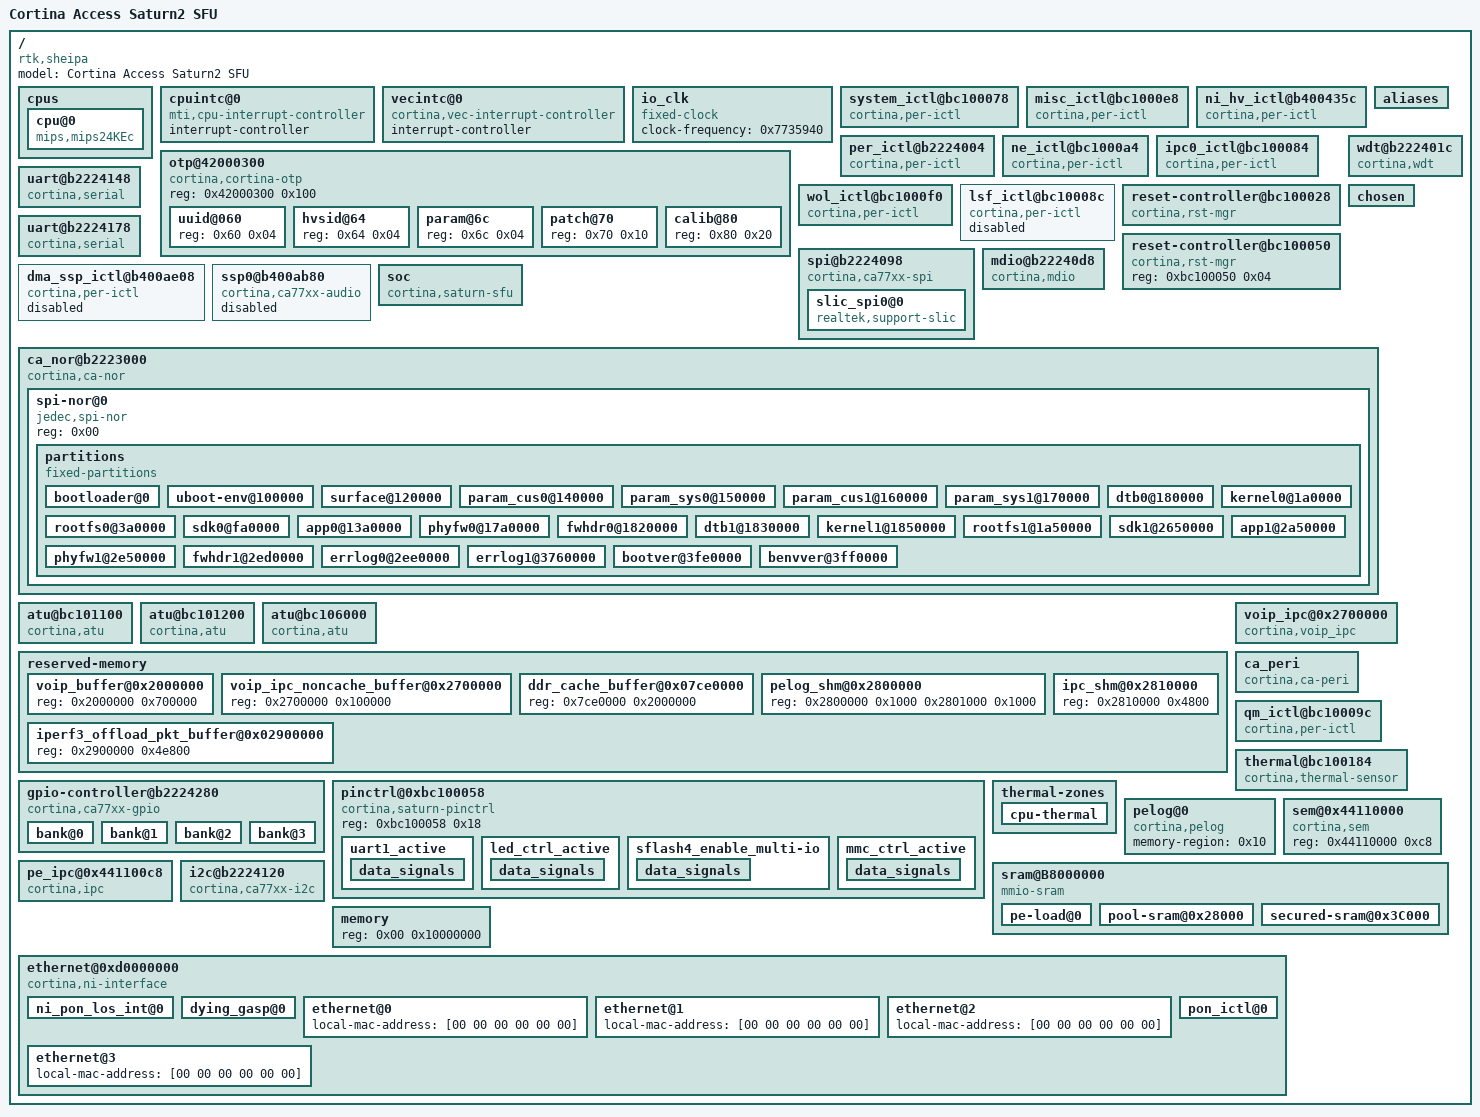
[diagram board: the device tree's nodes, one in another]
/dts-v1/;

/ {
	compatible = "rtk,sheipa";
	#address-cells = <0x01>;
	#size-cells = <0x01>;
	model = "Cortina Access Saturn2 SFU";

	cpus {
		#address-cells = <0x01>;
		#size-cells = <0x00>;

		cpu@0 {
			compatible = "mips,mips24KEc";
		};
	};

	cpuintc@0 {
		#address-cells = <0x00>;
		#interrupt-cells = <0x01>;
		interrupt-controller;
		compatible = "mti,cpu-interrupt-controller";
		linux,phandle = <0x01>;
		phandle = <0x01>;
	};

	vecintc@0 {
		#address-cells = <0x00>;
		#interrupt-cells = <0x01>;
		interrupt-controller;
		compatible = "cortina,vec-interrupt-controller";
		linux,phandle = <0x04>;
		phandle = <0x04>;
	};

	io_clk {
		compatible = "fixed-clock";
		#clock-cells = <0x00>;
		clock-frequency = <0x7735940>;
		linux,phandle = <0x05>;
		phandle = <0x05>;
	};

	otp@42000300 {
		compatible = "cortina,cortina-otp";
		#address-cells = <0x01>;
		#size-cells = <0x01>;
		reg = <0x42000300 0x100>;

		uuid@060 {
			reg = <0x60 0x04>;
		};

		hvsid@64 {
			reg = <0x64 0x04>;
		};

		param@6c {
			reg = <0x6c 0x04>;
			linux,phandle = <0x15>;
			phandle = <0x15>;
		};

		patch@70 {
			reg = <0x70 0x10>;
		};

		calib@80 {
			reg = <0x80 0x20>;
			linux,phandle = <0x16>;
			phandle = <0x16>;
		};
	};

	system_ictl@bc100078 {
		compatible = "cortina,per-ictl";
		reg = <0xbc100078 0x08>;
		interrupt-controller;
		#interrupt-cells = <0x01>;
		interrupt-parent = <0x01>;
		interrupts = <0x02>;
		linux,phandle = <0x02>;
		phandle = <0x02>;
	};

	misc_ictl@bc1000e8 {
		compatible = "cortina,per-ictl";
		reg = <0xbc1000e8 0x08>;
		interrupt-controller;
		#interrupt-cells = <0x01>;
		interrupt-parent = <0x02>;
		interrupts = <0x00>;
	};

	ni_hv_ictl@b400435c {
		compatible = "cortina,per-ictl";
		reg = <0xb400435c 0x08>;
		interrupt-controller;
		#interrupt-cells = <0x01>;
		interrupt-parent = <0x03>;
		interrupts = <0x00>;
		linux,phandle = <0x14>;
		phandle = <0x14>;
	};

	per_ictl@b2224004 {
		compatible = "cortina,per-ictl";
		reg = <0xb2224004 0x08>;
		interrupt-controller;
		#interrupt-cells = <0x01>;
		interrupt-parent = <0x01>;
		interrupts = <0x03>;
		linux,phandle = <0x06>;
		phandle = <0x06>;
	};

	ne_ictl@bc1000a4 {
		compatible = "cortina,per-ictl";
		reg = <0xbc1000a4 0x08>;
		interrupt-controller;
		#interrupt-cells = <0x01>;
		interrupt-parent = <0x04>;
		interrupts = <0x04>;
		linux,phandle = <0x03>;
		phandle = <0x03>;
	};

	ipc0_ictl@bc100084 {
		compatible = "cortina,per-ictl";
		reg = <0xbc100084 0x08>;
		interrupt-controller;
		#interrupt-cells = <0x01>;
		interrupt-parent = <0x04>;
		interrupts = <0x06>;
		linux,phandle = <0x12>;
		phandle = <0x12>;
	};

	wol_ictl@bc1000f0 {
		compatible = "cortina,per-ictl";
		reg = <0xbc1000f0 0x08>;
		interrupt-controller;
		#interrupt-cells = <0x01>;
		interrupt-parent = <0x03>;
		interrupts = <0x07>;
	};

	lsf_ictl@bc10008c {
		compatible = "cortina,per-ictl";
		reg = <0xbc10008c 0x08>;
		interrupt-controller;
		#interrupt-cells = <0x01>;
		interrupt-parent = <0x01>;
		interrupts = <0x05>;
		status = "disabled";
		linux,phandle = <0x08>;
		phandle = <0x08>;
	};

	reset-controller@bc100028 {
		compatible = "cortina,rst-mgr";
		reg = <0xbc100028 0x04>;
		#reset-cells = <0x01>;
		init-state = <0x4f28022e>;
		linux,phandle = <0x0d>;
		phandle = <0x0d>;
	};

	reset-controller@bc100050 {
		compatible = "cortina,rst-mgr";
		reg = <0xbc100050 0x04>;
		#reset-cells = <0x01>;
		linux,phandle = <0x17>;
		phandle = <0x17>;
	};

	aliases {
		serial0 = "/uart@b2224148";
		serial1 = "/uart@b2224178";
		ethernet0 = "/ethernet@0xd0000000/ethernet@0";
		ethernet1 = "/ethernet@0xd0000000/ethernet@1";
		ethernet2 = "/ethernet@0xd0000000/ethernet@2";
		ethernet3 = "/ethernet@0xd0000000/ethernet@3";
	};

	uart@b2224148 {
		device_type = "serial";
		compatible = "cortina,serial";
		reg = <0xb2224148 0x30>;
		clocks = <0x05>;
		interrupt-parent = <0x02>;
		interrupts = <0x04>;
	};

	uart@b2224178 {
		device_type = "serial";
		compatible = "cortina,serial";
		reg = <0xb2224178 0x30>;
		clocks = <0x05>;
		interrupt-parent = <0x02>;
		interrupts = <0x05>;
	};

	wdt@b222401c {
		compatible = "cortina,wdt";
		reg = <0xb222401c 0x30 0xbc100050 0x04>;
		interrupt-parent = <0x06>;
		interrupts = <0x04>;
		clocks = <0x05>;
		reset-on-timeout;
	};

	spi@b2224098 {
		compatible = "cortina,ca77xx-spi";
		reg = <0xb2224098 0x40>;
		interrupt-parent = <0x06>;
		interrupts = <0x05>;
		clocks = <0x05>;
		#address-cells = <0x01>;
		#size-cells = <0x00>;

		slic_spi0@0 {
			compatible = "realtek,support-slic";
			status = "okay";
			spi-max-frequency = <0x2625a0>;
			reg = <0x00>;
			reset-gpio = <0x07 0x0f 0x01>;
		};
	};

	dma_ssp_ictl@b400ae08 {
		compatible = "cortina,per-ictl";
		reg = <0xb400ae08 0x08>;
		interrupt-controller;
		#interrupt-cells = <0x01>;
		interrupt-parent = <0x08>;
		interrupts = <0x08>;
		status = "disabled";
		linux,phandle = <0x09>;
		phandle = <0x09>;
	};

	ssp0@b400ab80 {
		compatible = "cortina,ca77xx-audio";
		reg = <0xb400ab80 0x80 0xb400a064 0x08 0xb400aa80 0x80>;
		reg-names = "ssp\0dma-glb\0dma-ssp";
		interrupt-parent = <0x09>;
		interrupts = <0x06 0x02 0x03>;
		interrupt-names = "ssp\0dma-tx\0dma-rx";
		status = "disabled";
	};

	soc {
		compatible = "cortina,saturn-sfu";
		reg = <0xbc100000 0x04 0xbc109000 0x40 0xbc100034 0x04>;
		reg-names = "JTAG_ID\0CLOCK\0STRAP";
	};

	chosen {
		bootargs = "rd_start=0x86000000 rd_size=8018950 root=/dev/ram console=ttyS0,115200 rdinit=/sbin/init ";
	};

	mdio@b22240d8 {
		#address-cells = <0x01>;
		#size-cells = <0x00>;
		compatible = "cortina,mdio";
		reg = <0xb22240d8 0x48>;
		interrupt-parent = <0x06>;
		interrupts = <0x0c>;
		device_type = "mdio";
		clocks = <0x05>;
		clock-frequency = <0x7735940>;
	};

	ca_nor@b2223000 {
		compatible = "cortina,ca-nor";
		#address-cells = <0x01>;
		#size-cells = <0x00>;
		reg = <0xb2223000 0x50>;
		reg-names = "sflash-base";
		pinctrl-0 = <0x0a>;
		pinctrl-names = "default";

		spi-nor@0 {
			compatible = "jedec,spi-nor";
			reg = <0x00>;

			partitions {
				compatible = "fixed-partitions";
				#address-cells = <0x01>;
				#size-cells = <0x01>;

				bootloader@0 {
					label = "bootloader";
					reg = <0x00 0x100000>;
				};

				uboot-env@100000 {
					label = "uboot-env";
					reg = <0x100000 0x20000>;
				};

				surface@120000 {
					label = "surface";
					reg = <0x120000 0x20000>;
				};

				param_cus0@140000 {
					label = "param_cus0";
					reg = <0x140000 0x10000>;
				};

				param_sys0@150000 {
					label = "param_sys0";
					reg = <0x150000 0x10000>;
				};

				param_cus1@160000 {
					label = "param_cus1";
					reg = <0x160000 0x10000>;
				};

				param_sys1@170000 {
					label = "param_sys1";
					reg = <0x170000 0x10000>;
				};

				dtb0@180000 {
					label = "device-tree0";
					reg = <0x180000 0x20000>;
				};

				kernel0@1a0000 {
					label = "kernel0";
					reg = <0x1a0000 0x200000>;
				};

				rootfs0@3a0000 {
					label = "rootfs0";
					reg = <0x3a0000 0xc00000>;
				};

				sdk0@fa0000 {
					label = "sdk0";
					reg = <0xfa0000 0x400000>;
				};

				app0@13a0000 {
					label = "app0";
					reg = <0x13a0000 0x400000>;
				};

				phyfw0@17a0000 {
					label = "phyfw0";
					reg = <0x17a0000 0x80000>;
				};

				fwhdr0@1820000 {
					label = "fwhdr0";
					reg = <0x1820000 0x10000>;
				};

				dtb1@1830000 {
					label = "device-tree1";
					reg = <0x1830000 0x20000>;
				};

				kernel1@1850000 {
					label = "kernel1";
					reg = <0x1850000 0x200000>;
				};

				rootfs1@1a50000 {
					label = "rootfs1";
					reg = <0x1a50000 0xc00000>;
				};

				sdk1@2650000 {
					label = "sdk1";
					reg = <0x2650000 0x400000>;
				};

				app1@2a50000 {
					label = "app1";
					reg = <0x2a50000 0x400000>;
				};

				phyfw1@2e50000 {
					label = "phyfw1";
					reg = <0x2e50000 0x80000>;
				};

				fwhdr1@2ed0000 {
					label = "fwhdr1";
					reg = <0x2ed0000 0x10000>;
				};

				errlog0@2ee0000 {
					label = "errlog0";
					reg = <0x2ee0000 0x880000>;
				};

				errlog1@3760000 {
					label = "errlog1";
					reg = <0x3760000 0x880000>;
				};

				bootver@3fe0000 {
					label = "bootver";
					reg = <0x3fe0000 0x10000>;
				};

				benvver@3ff0000 {
					label = "benvver";
					reg = <0x3ff0000 0x10000>;
				};
			};
		};
	};

	atu@bc101100 {
		compatible = "cortina,atu";
		reg = <0xbc101100 0x1c>;
		reg-names = "taroko0_atu";
		atu-type = <0x00>;
		#iommu-cells = <0x00>;
		keep-init;
	};

	atu@bc101200 {
		compatible = "cortina,atu";
		reg = <0xbc101200 0x1c>;
		reg-names = "taroko1_atu";
		atu-type = <0x00>;
		#iommu-cells = <0x00>;
		keep-init;
	};

	atu@bc106000 {
		compatible = "cortina,atu";
		reg = <0xbc106000 0x1c>;
		reg-names = "eaxi_atu";
		atu-type = <0x00>;
		#iommu-cells = <0x00>;
		keep-init;
	};

	reserved-memory {
		#address-cells = <0x01>;
		#size-cells = <0x01>;
		ranges;

		voip_buffer@0x2000000 {
			reg = <0x2000000 0x700000>;
			linux,phandle = <0x0c>;
			phandle = <0x0c>;
		};

		voip_ipc_noncache_buffer@0x2700000 {
			reg = <0x2700000 0x100000>;
			linux,phandle = <0x0b>;
			phandle = <0x0b>;
		};

		ddr_cache_buffer@0x07ce0000 {
			reg = <0x7ce0000 0x2000000>;
			linux,phandle = <0x18>;
			phandle = <0x18>;
		};

		pelog_shm@0x2800000 {
			reg = <0x2800000 0x1000 0x2801000 0x1000>;
			linux,phandle = <0x10>;
			phandle = <0x10>;
		};

		ipc_shm@0x2810000 {
			reg = <0x2810000 0x4800>;
			linux,phandle = <0x11>;
			phandle = <0x11>;
		};

		iperf3_offload_pkt_buffer@0x02900000 {
			reg = <0x2900000 0x4e800>;
		};
	};

	voip_ipc@0x2700000 {
		compatible = "cortina,voip_ipc";
		reg = <0xb2224000 0x20 0x40000000 0x10>;
		memory-region = <0x0b 0x0c>;
		interrupt-parent = <0x06>;
		interrupts = <0x00>;
		resets = <0x0d 0x13 0x0d 0x15 0x0d 0x18>;
		reset-names = "pe_reset\0rcpu_reset\0pe_atu_reset";
	};

	ca_peri {
		compatible = "cortina,ca-peri";
		reg = <0xb2224018 0x1000 0xbc100000 0x200 0xba000800 0x10 0xba000000 0x400>;
		interrupt-parent = <0x06>;
		interrupts = <0x02>;
		interrupt-names = "TMR1";
	};

	qm_ictl@bc10009c {
		compatible = "cortina,per-ictl";
		reg = <0xbc10009c 0x08>;
		interrupt-controller;
		#interrupt-cells = <0x01>;
		interrupt-parent = <0x01>;
		interrupts = <0x04>;
		linux,phandle = <0x13>;
		phandle = <0x13>;
	};

	gpio-controller@b2224280 {
		#address-cells = <0x01>;
		#size-cells = <0x00>;
		compatible = "cortina,ca77xx-gpio";
		reg = <0xb2224280 0x90 0xbc100060 0x10>;
		id = <0x00>;

		bank@0 {
			gpio-controller;
			interrupt-controller;
			reg = <0x00>;
			ngpios = <0x20>;
			#gpio-cells = <0x02>;
			#interrupt-cells = <0x02>;
			interrupt-parent = <0x06>;
			interrupts = <0x06>;
			gpio-ranges = <0x0e 0x00 0x00 0x20>;
			linux,phandle = <0x07>;
			phandle = <0x07>;
		};

		bank@1 {
			gpio-controller;
			interrupt-controller;
			reg = <0x01>;
			ngpios = <0x20>;
			#gpio-cells = <0x02>;
			#interrupt-cells = <0x02>;
			interrupt-parent = <0x06>;
			interrupts = <0x07>;
			gpio-ranges = <0x0e 0x00 0x20 0x20>;
		};

		bank@2 {
			gpio-controller;
			interrupt-controller;
			reg = <0x02>;
			ngpios = <0x20>;
			#gpio-cells = <0x02>;
			#interrupt-cells = <0x02>;
			interrupt-parent = <0x06>;
			interrupts = <0x08>;
			gpio-ranges = <0x0e 0x00 0x40 0x20>;
		};

		bank@3 {
			gpio-controller;
			interrupt-controller;
			reg = <0x03>;
			ngpios = <0x20>;
			#gpio-cells = <0x02>;
			#interrupt-cells = <0x02>;
			interrupt-parent = <0x06>;
			interrupts = <0x09>;
			gpio-ranges = <0x0e 0x00 0x60 0x20>;
		};
	};

	pinctrl@0xbc100058 {
		compatible = "cortina,saturn-pinctrl";
		reg = <0xbc100058 0x18>;
		linux,phandle = <0x0e>;
		phandle = <0x0e>;

		uart1_active {

			data_signals {
				pins = "GPIO_000\0GPIO_001\0PMUX_003";
				function = "multi-fn";
			};
		};

		led_ctrl_active {

			data_signals {
				pins = "GPIO_006\0GPIO_007\0PMUX_004";
				function = "multi-fn";
			};
		};

		sflash4_enable_multi-io {
			linux,phandle = <0x0a>;
			phandle = <0x0a>;

			data_signals {
				pins = "PMUX_024";
				function = "multi-fn";
			};
		};

		mmc_ctrl_active {

			data_signals {
				pins = "GPIO_008\0GPIO_010\0PMUX_013";
				function = "multi-fn";
			};
		};
	};

	thermal@bc100184 {
		compatible = "cortina,thermal-sensor";
		reg = <0xbc100184 0x10>;
		status = "okay";
		#thermal-sensor-cells = <0x00>;
		tms-reg-a = <0x85fa000>;
		tms-reg-b = <0x36da00>;
		linux,phandle = <0x0f>;
		phandle = <0x0f>;
	};

	thermal-zones {

		cpu-thermal {
			polling-delay-passive = <0x1f4>;
			polling-delay = <0x3e8>;
			thermal-sensors = <0x0f>;
		};
	};

	pelog@0 {
		compatible = "cortina,pelog";
		memory-region = <0x10>;
	};

	sem@0x44110000 {
		compatible = "cortina,sem";
		reg = <0x44110000 0xc8>;
	};

	pe_ipc@0x441100c8 {
		compatible = "cortina,ipc";
		memory-region = <0x11>;
		reg = <0x441100c8 0x48>;
		interrupt-parent = <0x12>;
		interrupts = <0x02>;
		interrupt-names = "IPC_PE0";
		pe-ipc-cpuid = <0x01>;
	};

	sram@B8000000 {
		compatible = "mmio-sram";
		#address-cells = <0x01>;
		#size-cells = <0x01>;
		reg = <0xb8000000 0x3c000 0x40000000 0x3c000>;
		no-memory-wc;
		ranges = <0x00 0xb8000000 0x3c000>;

		pe-load@0 {
			reg = <0x00 0x100>;
			pool;
			export;
		};

		pool-sram@0x28000 {
			reg = <0x28000 0x14000>;
			pool;
			export;
		};

		secured-sram@0x3C000 {
			reg = <0x3c000 0x4000>;
			pool;
			export;
		};
	};

	i2c@b2224120 {
		compatible = "cortina,ca77xx-i2c";
		reg = <0xb2224120 0x28>;
		interrupt-parent = <0x06>;
		interrupts = <0x0b>;
		device_type = "i2c";
		clocks = <0x05>;
		clock-frequency = <0x186a0>;
	};

	memory {
		device_type = "memory";
		reg = <0x00 0x10000000>;
	};

	ethernet@0xd0000000 {
		compatible = "cortina,ni-interface";
		reg = <0xd0000000 0xa000 0x441000a4 0x10 0x522240d8 0x48 0xf4500000 0x2000 0xd000a000 0x900 0x7ce0000 0x2000000 0x2c48000 0x1000000 0xd000b000 0x1000 0xd000c000 0x2124 0xd000e000 0x40>;
		reg-names = "ni_hv\0glb_network\0mdio_cfg\0xram\0dma_lso\0ddr_cache\0ddr_noncache\0internal_phy\0xfi\0ptp";
		interrupts-extended = <0x13 0x08 0x13 0x09 0x13 0x0a 0x13 0x0b 0x13 0x0c 0x13 0x0d 0x13 0x0e 0x13 0x0f 0x13 0x10 0x13 0x11 0x02 0x07 0x03 0x10 0x14 0x11 0x14 0x12 0x14 0x1b>;
		interrupt-names = "cpu_epp_fifo_0\0cpu_epp_fifo_1\0cpu_epp_fifo_2\0cpu_epp_fifo_3\0cpu_epp_fifo_4\0cpu_epp_fifo_5\0cpu_epp_fifo_6\0cpu_epp_fifo_7\0cpu_refill_req0\0cpu_refill_req1\0ni_psds_prbs\0ni_ptp\0macsec_de\0macsec_en\0ptp_stat";
		nvmem-cells = <0x15 0x16>;
		nvmem-cell-names = "param\0calibration";
		resets = <0x0d 0x00 0x0d 0x01 0x0d 0x02 0x0d 0x03 0x0d 0x04 0x0d 0x05 0x0d 0x10 0x0d 0x1a 0x17 0x09>;
		reset-names = "ni_reset\0l2fe_reset\0l2tm_reset\0l3fe_reset\0sdram_reset\0tqm_reset\0dma_reset\0fbm_reset\0ext_reset";
		memory-region = <0x18>;
		dyinggasp-gpio = <0x07 0x01 0x01>;
		ni-pon-int-gpio = <0x07 0x0d 0x00>;

		ni_pon_los_int@0 {
			interrupt-parent = <0x07>;
			interrupts = <0x0d 0x03>;
			interrupt-names = "PON LOS ITNT";
		};

		dying_gasp@0 {
			interrupt-parent = <0x06>;
			interrupts = <0x18>;
			interrupt-names = "DYING GASP";
		};

		ethernet@0 {
			local-mac-address = [00 00 00 00 00 00];
		};

		ethernet@1 {
			local-mac-address = [00 00 00 00 00 00];
		};

		ethernet@2 {
			local-mac-address = [00 00 00 00 00 00];
		};

		ethernet@3 {
			local-mac-address = [00 00 00 00 00 00];
		};

		pon_ictl@0 {
			interrupt-controller;
			#interrupt-cells = <0x01>;
			interrupt-parent = <0x04>;
			interrupts = <0x02>;
		};
	};
};
